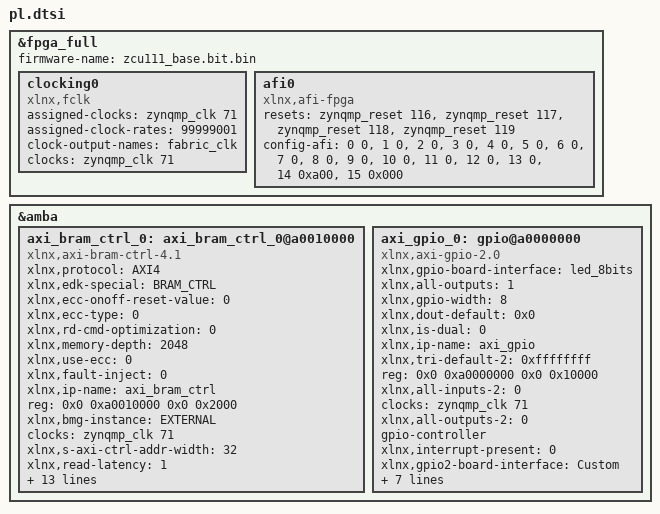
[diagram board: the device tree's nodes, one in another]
/dts-v1/;
/plugin/;
&fpga_full {
	firmware-name = "zcu111_base.bit.bin";
	clocking0: clocking0 {
		compatible = "xlnx,fclk";
		assigned-clocks = <&zynqmp_clk 71>;
		assigned-clock-rates = <99999001>;
		#clock-cells = <0>;
		clock-output-names = "fabric_clk";
		clocks = <&zynqmp_clk 71>;
	};
	afi0: afi0 {
		compatible = "xlnx,afi-fpga";
		resets = <&zynqmp_reset 116>, <&zynqmp_reset 117>, <&zynqmp_reset 118>, <&zynqmp_reset 119>;
		config-afi = < 0 0>, <1 0>, <2 0>, <3 0>, <4 0>, <5 0>, <6 0>, <7 0>, <8 0>, <9 0>, <10 0>, <11 0>, <12 0>, <13 0>, <14 0xa00>, <15 0x000>;
	};
};

&amba {
	axi_bram_ctrl_0: axi_bram_ctrl_0@a0010000 {
		xlnx,protocol = "AXI4";
		xlnx,edk-special = "BRAM_CTRL";
		compatible = "xlnx,axi-bram-ctrl-4.1" , "xlnx,axi-bram-ctrl";
		xlnx,ecc-onoff-reset-value = <0>;
		xlnx,ecc-type = <0>;
		xlnx,rd-cmd-optimization = <0>;
		xlnx,memory-depth = <2048>;
		xlnx,use-ecc = <0>;
		xlnx,fault-inject = <0>;
		xlnx,ip-name = "axi_bram_ctrl";
		reg = <0x0 0xa0010000 0x0 0x2000>;
		xlnx,bmg-instance = "EXTERNAL";
		clocks = <&zynqmp_clk 71>;
		xlnx,s-axi-ctrl-addr-width = <32>;
		xlnx,read-latency = <1>;
		xlnx,id-width = <0>;
		xlnx,s-axi-supports-narrow-burst = <1>;
		xlnx,supports-narrow-burst = <1>;
		xlnx,single-port-bram = <0>;
		xlnx,ecc = <0>;
		xlnx,edk-iptype = "PERIPHERAL";
		clock-names = "s_axi_aclk";
		xlnx,data-width = <32>;
		xlnx,bram-addr-width = <11>;
		xlnx,bram-inst-mode = "EXTERNAL";
		xlnx,s-axi-ctrl-data-width = <32>;
		xlnx,mem-depth = <2048>;
		xlnx,s-axi-id-width = <1>;
		xlnx,name = "axi_bram_ctrl_0";
	};
	axi_gpio_0: gpio@a0000000 {
		xlnx,gpio-board-interface = "led_8bits";
		compatible = "xlnx,axi-gpio-2.0" , "xlnx,xps-gpio-1.00.a";
		xlnx,all-outputs = <1>;
		#gpio-cells = <2>;
		xlnx,gpio-width = <8>;
		xlnx,dout-default = <0x0>;
		xlnx,is-dual = <0>;
		xlnx,ip-name = "axi_gpio";
		xlnx,tri-default-2 = <0xffffffff>;
		reg = <0x0 0xa0000000 0x0 0x10000>;
		xlnx,all-inputs-2 = <0>;
		clocks = <&zynqmp_clk 71>;
		xlnx,all-outputs-2 = <0>;
		gpio-controller;
		xlnx,interrupt-present = <0>;
		xlnx,gpio2-board-interface = "Custom";
		xlnx,edk-iptype = "PERIPHERAL";
		xlnx,dout-default-2 = <0x0>;
		xlnx,gpio2-width = <32>;
		clock-names = "s_axi_aclk";
		xlnx,use-board-flow;
		xlnx,tri-default = <0xffffffff>;
		xlnx,name = "axi_gpio_0";
		xlnx,all-inputs = <0>;
	};
};
